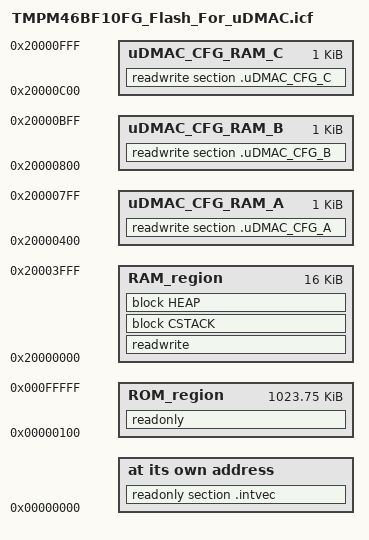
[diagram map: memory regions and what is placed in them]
/*###ICF### Section handled by ICF editor, don't touch! ****/
/*-Editor annotation file-*/
/* IcfEditorFile="$TOOLKIT_DIR$\config\ide\IcfEditor\a_v1_0.xml" */
/*-Specials-*/
define symbol __ICFEDIT_intvec_start__ = 0x00000000;
/*-Memory Regions-*/
define symbol __ICFEDIT_region_ROM_start__   = 0x00000100;
define symbol __ICFEDIT_region_ROM_end__     = 0x000FFFFF;


define symbol __ICFEDIT_region_RAM_start__   = 0x20000000;
define symbol __ICFEDIT_region_RAM_end__     = 0x20003FFF;

/* reserve 1K RAM for uDMAC configuration */
define symbol uDMAC_RAM_START_A = 0x20000400; 
define symbol uDMAC_RAM_END_A   = 0x200007FF; 
define symbol uDMAC_RAM_START_B = 0x20000800; 
define symbol uDMAC_RAM_END_B   = 0x20000BFF; 
define symbol uDMAC_RAM_START_C = 0x20000C00; 
define symbol uDMAC_RAM_END_C   = 0x20000FFF; 


/*-Sizes-*/
define symbol __ICFEDIT_size_cstack__   = 0x200;
define symbol __ICFEDIT_size_heap__     = 0x200;
/**** End of ICF editor section. ###ICF###*/


define memory mem with size = 4G;
define region ROM_region   = mem:[from __ICFEDIT_region_ROM_start__   to __ICFEDIT_region_ROM_end__];
define region RAM_region   = mem:[from __ICFEDIT_region_RAM_start__   to __ICFEDIT_region_RAM_end__];

define region uDMAC_CFG_RAM_A  = mem:[from uDMAC_RAM_START_A to uDMAC_RAM_END_A]; 
define region uDMAC_CFG_RAM_B  = mem:[from uDMAC_RAM_START_B to uDMAC_RAM_END_B];
define region uDMAC_CFG_RAM_C  = mem:[from uDMAC_RAM_START_C to uDMAC_RAM_END_C];

define block CSTACK    with alignment = 8, size = __ICFEDIT_size_cstack__   { };
define block HEAP      with alignment = 8, size = __ICFEDIT_size_heap__     { };

initialize by copy { readwrite };
do not initialize  { section .noinit };

place at address mem:__ICFEDIT_intvec_start__ { readonly section .intvec };

place in ROM_region   { readonly };
place in RAM_region   { readwrite,
                        block CSTACK, block HEAP };

place in  uDMAC_CFG_RAM_A   { readwrite section .uDMAC_CFG_A }; 
place in  uDMAC_CFG_RAM_B   { readwrite section .uDMAC_CFG_B }; 
place in  uDMAC_CFG_RAM_C   { readwrite section .uDMAC_CFG_C }; 
